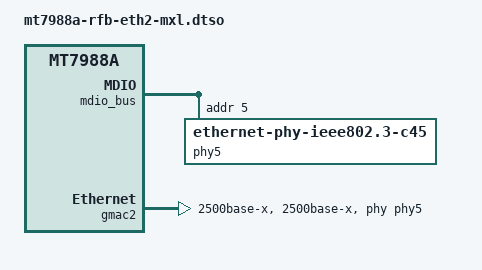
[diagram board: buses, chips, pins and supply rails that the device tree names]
// SPDX-License-Identifier: (GPL-2.0 OR MIT)
/*
 * Copyright (C) 2022 MediaTek Inc.
 * Author: Sam.Shih <sam.shih@mediatek.com>
 */

/dts-v1/;
/plugin/;

#include <dt-bindings/gpio/gpio.h>

/ {
	compatible = "mediatek,mt7988a-rfb", "mediatek,mt7988a";

	fragment@0 {
		target = <&mdio_bus>;
		__overlay__ {
			#address-cells = <1>;
			#size-cells = <0>;

			/* external Maxlinear GPY211C */
			phy5: ethernet-phy@5 {
				reg = <5>;
				compatible = "ethernet-phy-ieee802.3-c45";
				phy-mode = "2500base-x";
			};
		};
	};

	fragment@1 {
		target = <&gmac2>;
		__overlay__ {
			phy-mode = "2500base-x";
			phy-connection-type = "2500base-x";
			phy = <&phy5>;
			status = "okay";
		};
	};
};
